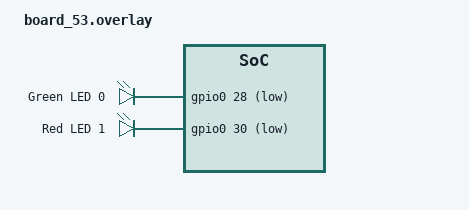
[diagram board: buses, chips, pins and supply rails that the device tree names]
/*
 * Copyright (c) 2023 Raytac Corporation
 *
 * SPDX-License-Identifier: Apache-2.0
 */

/ {
	//model = "Raytac MDBT53-DB-40 NRF5340 Application";
	//compatible = "raytac,raytac-mdbt53-db-40-nrf5340-cpuapp";

	//chosen {
	//	zephyr,ieee802154 = &ieee802154;
	//}

	leds {
		compatible = "gpio-leds";
		led0: led_0 {
			gpios = <&gpio0 28 GPIO_ACTIVE_LOW>;
			label = "Green LED 0";
		};
		led1: led_1 {
			gpios = <&gpio0 30 GPIO_ACTIVE_LOW>;
			label = "Red LED 1";
		};
	};
};


//zephyr_udc0: &usbd {
//	compatible = "nordic,nrf-usbd";
//	status = "okay";
//};
